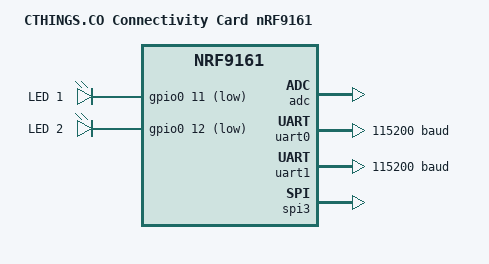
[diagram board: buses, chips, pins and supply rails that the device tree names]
/*
 * Copyright (c) 2024 CTHINGS.CO
 *
 * SPDX-License-Identifier: Apache-2.0
 */

#include "ctcc_nrf9161-pinctrl.dtsi"
#include <zephyr/dt-bindings/input/input-event-codes.h>

/ {
	model = "CTHINGS.CO Connectivity Card nRF9161";
	compatible = "ct,ctcc-nrf9161";

	chosen {
		zephyr,console = &uart0;
		zephyr,shell-uart = &uart0;
		zephyr,uart-mcumgr = &uart0;
	};

	leds {
		 compatible = "gpio-leds";
		 led1: led_1 {
			 gpios = <&gpio0 11 GPIO_ACTIVE_LOW>;
			 label = "LED 1";
		 };
		 led2: led_2 {
			 gpios = <&gpio0 12 GPIO_ACTIVE_LOW>;
			 label = "LED 2";
		 };
	};

	aliases {
		led0 = &led1;
		led1 = &led2;
		mcuboot-led0 = &led1;
		bootloader-led0 = &led1;
		watchdog0 = &wdt0;
		spi-flash0 = &mx25r6435;
	};
};

&adc {
	status = "okay";
};

&gpiote {
	status = "okay";
};

&gpio0 {
	status = "okay";
};

&uart0 {
	status = "okay";
	current-speed = <115200>;
	pinctrl-0 = <&uart0_default>;
	pinctrl-1 = <&uart0_sleep>;
	pinctrl-names = "default", "sleep";
};

&uart1 {
	status = "okay";
	current-speed = <115200>;
	pinctrl-0 = <&uart1_default>;
	pinctrl-1 = <&uart1_sleep>;
	pinctrl-names = "default", "sleep";
};

&spi3 {
	compatible = "nordic,nrf-spim";
	status = "okay";
	cs-gpios = <&gpio0 16 GPIO_ACTIVE_LOW>;
	pinctrl-0 = <&spi3_default>;
	pinctrl-1 = <&spi3_sleep>;
	pinctrl-names = "default", "sleep";

	mx25r6435: mx25r6435fm2il0@0 {
		compatible = "jedec,spi-nor";
		status = "disabled";
		reg = <0>;
		spi-max-frequency = <10000000>;
		size = <DT_SIZE_M(64)>;
		has-dpd;
		dpd-wakeup-sequence = <30000>, <20>, <30000>;
		jedec-id = [c2 25 38];
	};
};

/* Include default memory partition configuration file */
#include <common/nordic/nrf91xx_partition.dtsi>
